# MCXC444 register map
Vendor: NXP Semiconductors; Series: MCX; File version: 1.6
CPU: CM0PLUS r0p0, little endian, no MPU, no FPU, VTOR, 2 interrupt priority bits
Registers are 32-bit, read-write, reset 0x0 unless marked. A register's access mark holds for its fields unless they carry their own. Offsets are from the block's base; [hi:lo] are bit positions; {n}, {i} and the like mark numbered series; 'fields as' and 'values as' point back to an identical list.

## DMA — DMA Controller
Base 0x40008000; register names take the prefix DMA_
{0x100+0x10*i} SAR{i} (i=0..3) — Source Address Register
  [31:0] SAR
{0x104+0x10*i} DAR{i} (i=0..3) — Destination Address Register
  [31:0] DAR
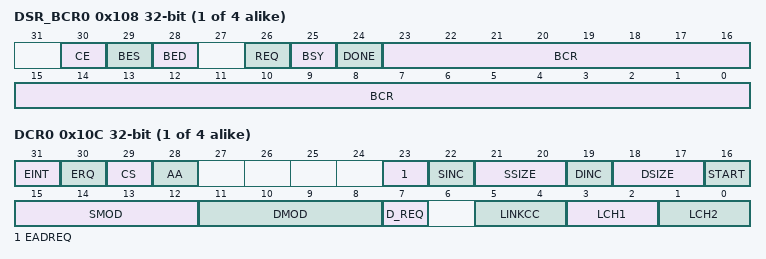
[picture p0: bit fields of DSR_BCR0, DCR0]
{0x108+0x10*i} DSR_BCR{i} (i=0..3) — DMA Status Register / Byte Count Register
  [30] CE ro — Configuration Error
    0=b0 (No configuration error exists.); 1=b1 (A configuration error has occurred.)
  [29] BES ro — Bus Error on Source
    0=b0 (No bus error occurred.); 1=b1 (The DMA channel terminated with a bus error during the read portion of a transfer.)
  [28] BED ro — Bus Error on Destination
    0=b0 (No bus error occurred.); 1=b1 (The DMA channel terminated with a bus error during the write portion of a transfer.)
  [26] REQ ro — Request
    0=b0 (No request is pending or the channel is currently active. Cleared when the channel is selected.); 1=b1 (The DMA channel has a transfer remaining and the channel is not selected.)
  [25] BSY ro — Busy
    0=b0 (DMA channel is inactive. Cleared when the DMA has finished the last transaction.); 1=b1 (BSY is set the first time the channel is enabled after a transfer is initiated.)
  [24] DONE — Transactions Done
    0=b0 (DMA transfer is not yet complete. Writing a 0 has no effect.); 1=b1 (DMA transfer completed. Writing a 1 to this bit clears all DMA status bits and should be used in an interrupt service routine to clear the DMA interrupt and error bits.)
  [23:0] BCR
{0x10B+0x10*i} DSR{i} 8-bit (i=0..3) — DMA_DSR{i} register.
{0x10C+0x10*i} DCR{i} (i=0..3) — DMA Control Register
  [31] EINT — Enable Interrupt on Completion of Transfer
    0=b0 (No interrupt is generated.); 1=b1 (Interrupt signal is enabled.)
  [30] ERQ — Enable Peripheral Request
    0=b0 (Peripheral request is ignored.); 1=b1 (Enables peripheral request to initiate transfer. A software-initiated request (setting START) is always enabled.)
  [29] CS — Cycle Steal
    0=b0 (DMA continuously makes read/write transfers until the BCR decrements to 0.); 1=b1 (Forces a single read/write transfer per request.)
  [28] AA — Auto-align
    0=b0 (Auto-align disabled); 1=b1 (If SSIZE indicates a transfer no smaller than DSIZE, source accesses are auto-aligned; otherwise, destination accesses are auto-aligned. Source alignment takes precedence over destination alignment. If auto-alignment is enabled, the appropriate address register increments, regardless of DINC or SINC.)
  [23] EADREQ — Enable asynchronous DMA requests
    0=b0 (Disabled); 1=b1 (Enabled)
  [22] SINC — Source Increment
    0=b0 (No change to SAR after a successful transfer.); 1=b1 (The SAR increments by 1, 2, 4 as determined by the transfer size.)
  [21:20] SSIZE — Source Size
    0=b00 (32-bit); 1=b01 (8-bit); 2=b10 (16-bit); 3=b11 (Reserved (generates a configuration error (DSRn[CE]) if incorrectly specified at time of channel activation))
  [19] DINC — Destination Increment
    0=b0 (No change to the DAR after a successful transfer.); 1=b1 (The DAR increments by 1, 2, 4 depending upon the size of the transfer.)
  [18:17] DSIZE — Destination Size
    values as SSIZE
  [16] START — Start Transfer
    0=b0 (DMA inactive); 1=b1 (The DMA begins the transfer in accordance to the values in the TCDn. START is cleared automatically after one module clock and always reads as logic 0.)
  [15:12] SMOD — Source Address Modulo
    0=b0000 (Buffer disabled); 1=b0001 (Circular buffer size is 16 bytes.); 2=b0010 (Circular buffer size is 32 bytes.); 3=b0011 (Circular buffer size is 64 bytes.); 4=b0100 (Circular buffer size is 128 bytes.); 5=b0101 (Circular buffer size is 256 bytes.); 6=b0110 (Circular buffer size is 512 bytes.); 7=b0111 (Circular buffer size is 1 KB.); 8=b1000 (Circular buffer size is 2 KB.); 9=b1001 (Circular buffer size is 4 KB.); 10=b1010 (Circular buffer size is 8 KB.); 11=b1011 (Circular buffer size is 16 KB.); 12=b1100 (Circular buffer size is 32 KB.); 13=b1101 (Circular buffer size is 64 KB.); 14=b1110 (Circular buffer size is 128 KB.); 15=b1111 (Circular buffer size is 256 KB.)
  [11:8] DMOD — Destination Address Modulo
    0=b0000 (Buffer disabled); 1=b0001 (Circular buffer size is 16 bytes); 2=b0010 (Circular buffer size is 32 bytes); 3=b0011 (Circular buffer size is 64 bytes); 4=b0100 (Circular buffer size is 128 bytes); 5=b0101 (Circular buffer size is 256 bytes); 6=b0110 (Circular buffer size is 512 bytes); 7=b0111 (Circular buffer size is 1 KB); 8=b1000 (Circular buffer size is 2 KB); 9=b1001 (Circular buffer size is 4 KB); 10=b1010 (Circular buffer size is 8 KB); 11=b1011 (Circular buffer size is 16 KB); 12=b1100 (Circular buffer size is 32 KB); 13=b1101 (Circular buffer size is 64 KB); 14=b1110 (Circular buffer size is 128 KB); 15=b1111 (Circular buffer size is 256 KB)
  [7] D_REQ — Disable Request
    0=b0 (ERQ bit is not affected.); 1=b1 (ERQ bit is cleared when the BCR is exhausted.)
  [5:4] LINKCC — Link Channel Control
    0=b00 (No channel-to-channel linking); 1=b01 (Perform a link to channel LCH1 after each cycle-steal transfer followed by a link to LCH2 after the BCR decrements to 0.); 2=b10 (Perform a link to channel LCH1 after each cycle-steal transfer); 3=b11 (Perform a link to channel LCH1 after the BCR decrements to 0.)
  [3:2] LCH1 — Link Channel 1
    0=b00 (DMA Channel 0); 1=b01 (DMA Channel 1); 2=b10 (DMA Channel 2); 3=b11 (DMA Channel 3)
  [1:0] LCH2 — Link Channel 2
    values as LCH1
